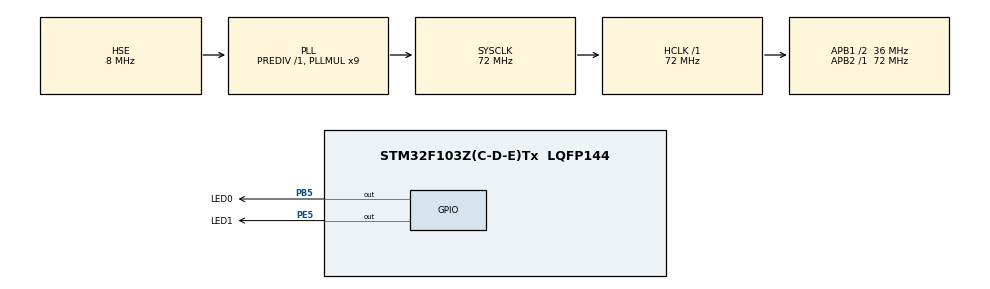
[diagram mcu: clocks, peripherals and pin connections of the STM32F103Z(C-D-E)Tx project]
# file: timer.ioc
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Mcu.Family=STM32F1
Mcu.Name=STM32F103Z(C-D-E)Tx
Mcu.Package=LQFP144
NVIC.PriorityGroup=NVIC_PRIORITYGROUP_4
NVIC.TIM2_IRQn=true\:0\:0\:false\:false\:true\:true\:true\:true
OSC_IN.Mode=HSE-External-Oscillator
OSC_IN.Signal=RCC_OSC_IN
OSC_OUT.Mode=HSE-External-Oscillator
OSC_OUT.Signal=RCC_OSC_OUT
PA13.Mode=JTAG_4_pins
PA13.Signal=SYS_JTMS-SWDIO
PA14.Mode=JTAG_4_pins
PA14.Signal=SYS_JTCK-SWCLK
PA15.Mode=JTAG_4_pins
PA15.Signal=SYS_JTDI
PB3.Mode=JTAG_4_pins
PB3.Signal=SYS_JTDO-TRACESWO
PB5.GPIO_Label=LED0
PB5.GPIO_PuPd=GPIO_PULLUP
PB5.GPIO_Speed=GPIO_SPEED_FREQ_HIGH
PB5.Signal=GPIO_Output
PC14-OSC32_IN.Mode=LSE-External-Oscillator
PC14-OSC32_IN.Signal=RCC_OSC32_IN
PC15-OSC32_OUT.Mode=LSE-External-Oscillator
PC15-OSC32_OUT.Signal=RCC_OSC32_OUT
PE5.GPIO_Label=LED1
PE5.GPIO_PuPd=GPIO_PULLUP
PE5.GPIO_Speed=GPIO_SPEED_FREQ_HIGH
PE5.Signal=GPIO_Output
ProjectManager.HeapSize=0x200
ProjectManager.StackSize=0x400
ProjectManager.TargetToolchain=STM32CubeIDE
RCC.AHBFreq_Value=72000000
RCC.APB1CLKDivider=RCC_HCLK_DIV2
RCC.APB1Freq_Value=36000000
RCC.APB1TimFreq_Value=72000000
RCC.APB2Freq_Value=72000000
RCC.APB2TimFreq_Value=72000000
RCC.HCLKFreq_Value=72000000
RCC.PLLMUL=RCC_PLL_MUL9
RCC.PLLSourceVirtual=RCC_PLLSOURCE_HSE
RCC.SYSCLKFreq_VALUE=72000000
RCC.SYSCLKSource=RCC_SYSCLKSOURCE_PLLCLK
RCC.USBFreq_Value=72000000
TIM2.AutoReloadPreload=TIM_AUTORELOAD_PRELOAD_ENABLE
TIM2.Period=9999
TIM2.Prescaler=7200
TIM2.TIM_MasterOutputTrigger=TIM_TRGO_RESET
VP_TIM2_VS_ClockSourceINT.Mode=Internal
board=custom

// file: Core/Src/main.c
/* USER CODE BEGIN Header */
/**
  ******************************************************************************
  * @file           : main.c
  * @brief          : Main program body
  ******************************************************************************
  * @attention
  *
  * Copyright (c) 2022 STMicroelectronics.
  * All rights reserved.
  *
  * This software is licensed under terms that can be found in the LICENSE file
  * in the root directory of this software component.
  * If no LICENSE file comes with this software, it is provided AS-IS.
  *
  ******************************************************************************
  */
/* USER CODE END Header */
#include "main.h"

 TIM_HandleTypeDef htim2;

void SystemClock_Config(void);
static void MX_GPIO_Init(void);
static void MX_TIM2_Init(void);

int main(void)
{

  /* MCU Configuration--------------------------------------------------------*/

  /* Reset of all peripherals, Initializes the Flash interface and the Systick. */
  HAL_Init();

  /* Configure the system clock */
  SystemClock_Config();

  /* Initialize all configured peripherals */
  MX_GPIO_Init();
  MX_TIM2_Init();

  /* Infinite loop */
  while (1)
  {

  }
}

void SystemClock_Config(void)
{
  RCC_OscInitTypeDef RCC_OscInitStruct = {0};
  RCC_ClkInitTypeDef RCC_ClkInitStruct = {0};

  /** Initializes the RCC Oscillators according to the specified parameters
  * in the RCC_OscInitTypeDef structure.
  */
  RCC_OscInitStruct.OscillatorType = RCC_OSCILLATORTYPE_HSE;
  RCC_OscInitStruct.HSEState = RCC_HSE_ON;
  RCC_OscInitStruct.HSEPredivValue = RCC_HSE_PREDIV_DIV1;
  RCC_OscInitStruct.HSIState = RCC_HSI_ON;
  RCC_OscInitStruct.PLL.PLLState = RCC_PLL_ON;
  RCC_OscInitStruct.PLL.PLLSource = RCC_PLLSOURCE_HSE;
  RCC_OscInitStruct.PLL.PLLMUL = RCC_PLL_MUL9;
  if (HAL_RCC_OscConfig(&RCC_OscInitStruct) != HAL_OK)
  {
    Error_Handler();
  }

  /** Initializes the CPU, AHB and APB buses clocks
  */
  RCC_ClkInitStruct.ClockType = RCC_CLOCKTYPE_HCLK|RCC_CLOCKTYPE_SYSCLK
                              |RCC_CLOCKTYPE_PCLK1|RCC_CLOCKTYPE_PCLK2;
  RCC_ClkInitStruct.SYSCLKSource = RCC_SYSCLKSOURCE_PLLCLK;
  RCC_ClkInitStruct.AHBCLKDivider = RCC_SYSCLK_DIV1;
  RCC_ClkInitStruct.APB1CLKDivider = RCC_HCLK_DIV2;
  RCC_ClkInitStruct.APB2CLKDivider = RCC_HCLK_DIV1;

  if (HAL_RCC_ClockConfig(&RCC_ClkInitStruct, FLASH_LATENCY_2) != HAL_OK)
  {
    Error_Handler();
  }
}

static void MX_TIM2_Init(void)
{

  TIM_ClockConfigTypeDef sClockSourceConfig = {0};
  TIM_MasterConfigTypeDef sMasterConfig = {0};

  htim2.Instance = TIM2;
  htim2.Init.Prescaler = 7200;
  htim2.Init.CounterMode = TIM_COUNTERMODE_UP;
  htim2.Init.Period = 9999;
  htim2.Init.ClockDivision = TIM_CLOCKDIVISION_DIV1;
  htim2.Init.AutoReloadPreload = TIM_AUTORELOAD_PRELOAD_ENABLE;
  if (HAL_TIM_Base_Init(&htim2) != HAL_OK)
  {
    Error_Handler();
  }
  sClockSourceConfig.ClockSource = TIM_CLOCKSOURCE_INTERNAL;
  if (HAL_TIM_ConfigClockSource(&htim2, &sClockSourceConfig) != HAL_OK)
  {
    Error_Handler();
  }
  sMasterConfig.MasterOutputTrigger = TIM_TRGO_RESET;
  sMasterConfig.MasterSlaveMode = TIM_MASTERSLAVEMODE_DISABLE;
  if (HAL_TIMEx_MasterConfigSynchronization(&htim2, &sMasterConfig) != HAL_OK)
  {
    Error_Handler();
  }
  /* USER CODE BEGIN TIM2_Init 2 */
  //启动定时器
  HAL_TIM_Base_Start_IT(&htim2);
  /* USER CODE END TIM2_Init 2 */

}

static void MX_GPIO_Init(void)
{
  GPIO_InitTypeDef GPIO_InitStruct = {0};

  /* GPIO Ports Clock Enable */
  __HAL_RCC_GPIOE_CLK_ENABLE();
  __HAL_RCC_GPIOC_CLK_ENABLE();
  __HAL_RCC_GPIOA_CLK_ENABLE();
  __HAL_RCC_GPIOB_CLK_ENABLE();

  /*Configure GPIO pin Output Level */
  HAL_GPIO_WritePin(LED1_GPIO_Port, LED1_Pin, GPIO_PIN_RESET);

  /*Configure GPIO pin Output Level */
  HAL_GPIO_WritePin(LED0_GPIO_Port, LED0_Pin, GPIO_PIN_RESET);

  /*Configure GPIO pin : LED1_Pin */
  GPIO_InitStruct.Pin = LED1_Pin;
  GPIO_InitStruct.Mode = GPIO_MODE_OUTPUT_PP;
  GPIO_InitStruct.Pull = GPIO_PULLUP;
  GPIO_InitStruct.Speed = GPIO_SPEED_FREQ_HIGH;
  HAL_GPIO_Init(LED1_GPIO_Port, &GPIO_InitStruct);

  /*Configure GPIO pin : LED0_Pin */
  GPIO_InitStruct.Pin = LED0_Pin;
  GPIO_InitStruct.Mode = GPIO_MODE_OUTPUT_PP;
  GPIO_InitStruct.Pull = GPIO_PULLUP;
  GPIO_InitStruct.Speed = GPIO_SPEED_FREQ_HIGH;
  HAL_GPIO_Init(LED0_GPIO_Port, &GPIO_InitStruct);

}

/* USER CODE BEGIN 4 */
void HAL_TIM_PeriodElapsedCallback(TIM_HandleTypeDef *htim)
{
	HAL_GPIO_TogglePin(LED0_GPIO_Port, LED0_Pin);
	HAL_GPIO_TogglePin(LED1_GPIO_Port, LED1_Pin);
}
/* USER CODE END 4 */

void Error_Handler(void)
{
  __disable_irq();
  while (1)
  {
  }
}
